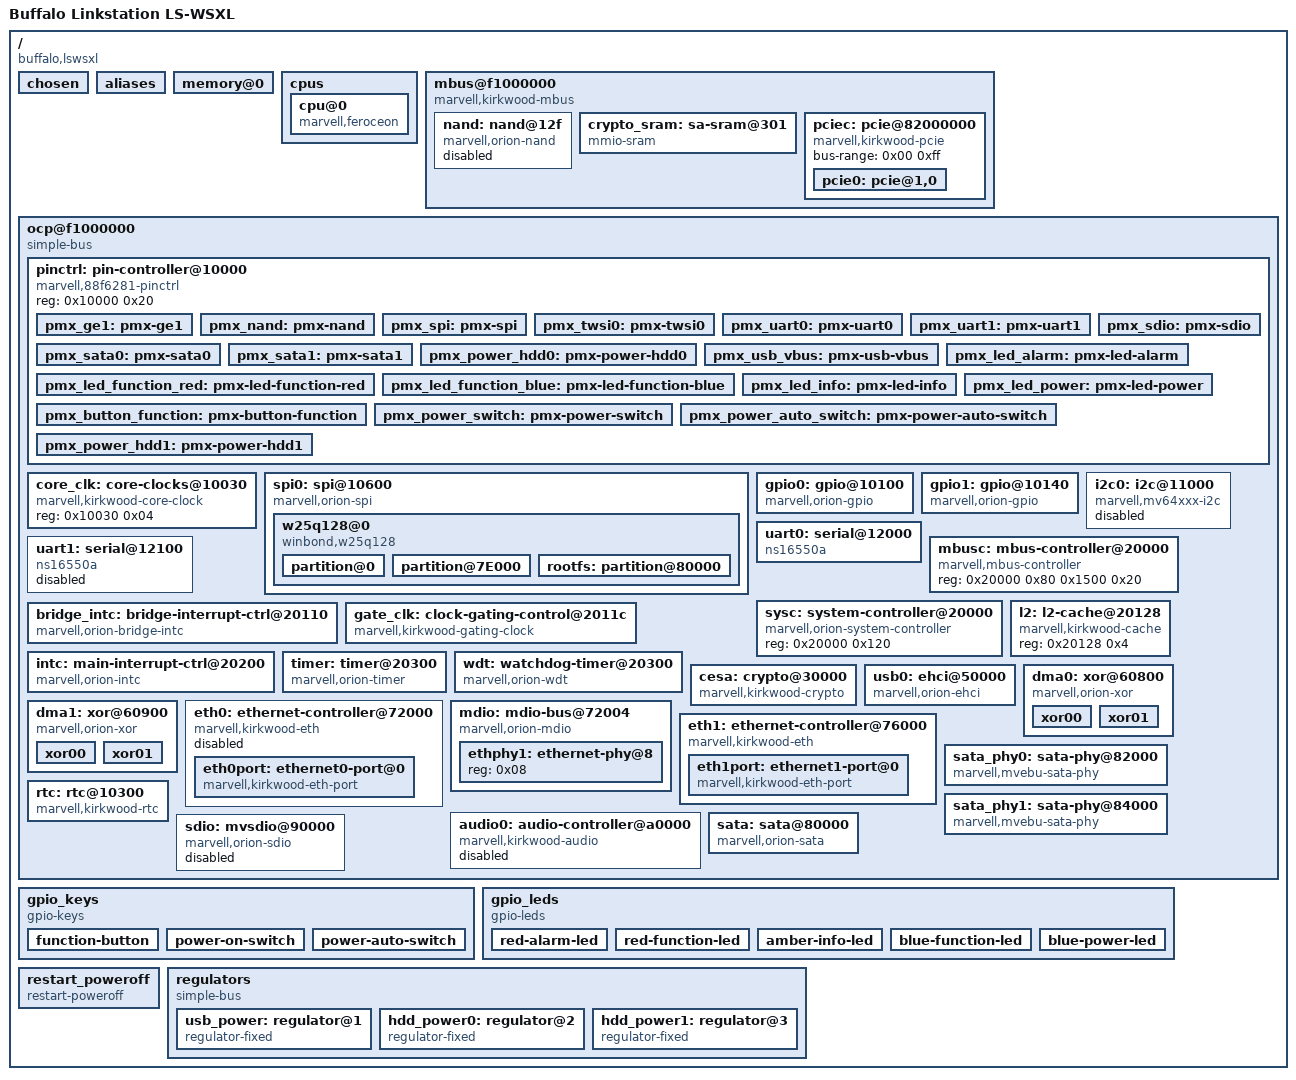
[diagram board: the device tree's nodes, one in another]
/dts-v1/;

#include <dt-bindings/input/input.h>
#include <dt-bindings/gpio/gpio.h>

#define MBUS_ID(target,attributes) (((target) << 24) | ((attributes) << 16))

/ {
	#address-cells = <0x01>;
	#size-cells = <0x01>;
	compatible = "buffalo,lswsxl", "marvell,kirkwood-88f6281", "marvell,kirkwood";
	interrupt-parent = <&intc>;
	model = "Buffalo Linkstation LS-WSXL";

	chosen {
		bootargs = "console=ttyS0,115200n8 earlyprintk ubi.mtd=rootfs root=/dev/ubiblock0_1 rootwait";
		stdout-path = &uart0;
	};

	aliases {
	       gpio0 = &gpio0;
	       gpio1 = &gpio1;
	       i2c0 = &i2c0;
	};

	memory@0 { /* 128 MB */
		name = "memory";
		device_type = "memory";
		reg = <0x00000000 0x8000000>;
	};

	cpus {
		#address-cells = <0x01>;
		#size-cells = <0x00>;

		cpu@0 {
			device_type = "cpu";
			compatible = "marvell,feroceon";
			reg = <0x00>;
			clocks = <&core_clk 1>, <&core_clk 3>, <&gate_clk 11>;
			clock-names = "cpu_clk", "ddrclk", "powersave";
		};
	};

	mbus@f1000000 {
		compatible = "marvell,kirkwood-mbus", "simple-bus";
		#address-cells = <0x02>;
		#size-cells = <0x01>;
		/* If a board file needs to change this ranges it must replace it completely */
		ranges = <MBUS_ID(0xf0, 0x01) 0 0xf1000000 0x100000	/* internal-regs */
			  MBUS_ID(0x01, 0x2f) 0 0xf4000000 0x10000	/* nand flash */
			  MBUS_ID(0x03, 0x01) 0 0xf5000000 0x10000	/* crypto sram */
			  >;
		controller = <&mbusc>;
		pcie-mem-aperture = <0xe0000000 0x10000000>; /* 256 MiB memory space */
		pcie-io-aperture  = <0xf2000000 0x100000>;   /*   1 MiB    I/O space */

		nand: nand@12f {
			#address-cells = <1>;
			#size-cells = <1>;
			cle = <0>;
			ale = <1>;
			bank-width = <1>;
			compatible = "marvell,orion-nand";
			reg = <MBUS_ID(0x01, 0x2f) 0 0x400>;
			chip-delay = <25>;
			/* set partition map and/or chip-delay in board dts */
			clocks = <&gate_clk 7>;
			pinctrl-0 = <&pmx_nand>;
			pinctrl-names = "default";
			status = "disabled";
		};

		crypto_sram: sa-sram@301 {
			compatible = "mmio-sram";
			reg = <MBUS_ID(0x03, 0x01) 0x0 0x800>;
			clocks = <&gate_clk 17>;
			#address-cells = <1>;
			#size-cells = <1>;
		};

		pciec: pcie@82000000 {
			compatible = "marvell,kirkwood-pcie";
			status = "okay";
			device_type = "pci";
			#address-cells = <0x03>;
			#size-cells = <0x02>;
			bus-range = <0x00 0xff>;

			ranges =
			       <0x82000000 0 0x40000 MBUS_ID(0xf0, 0x01) 0x40000 0 0x00002000
				0x82000000 0x1 0     MBUS_ID(0x04, 0xe8) 0       1 0 /* Port 0.0 MEM */
				0x81000000 0x1 0     MBUS_ID(0x04, 0xe0) 0       1 0 /* Port 0.0 IO  */>;

			pcie0: pcie@1,0 {
				device_type = "pci";
				assigned-addresses = <0x82000800 0 0x00040000 0 0x2000>;
				reg = <0x0800 0 0 0 0>;
				#address-cells = <3>;
				#size-cells = <2>;
				#interrupt-cells = <1>;
				ranges = <0x82000000 0 0 0x82000000 0x1 0 1 0
					  0x81000000 0 0 0x81000000 0x1 0 1 0>;
				bus-range = <0x00 0xff>;
				interrupt-map-mask = <0 0 0 0>;
				interrupt-map = <0 0 0 0 &intc 9>;
				marvell,pcie-port = <0>;
				marvell,pcie-lane = <0>;
				clocks = <&gate_clk 2>;
				status = "okay";
			};
		};
	};

	ocp@f1000000 {
		compatible = "simple-bus";
		ranges = <0x00 0xf1000000 0x100000>;
		#address-cells = <0x01>;
		#size-cells = <0x01>;

		pinctrl: pin-controller@10000 {
			reg = <0x10000 0x20>;
			compatible = "marvell,88f6281-pinctrl";

			pmx_ge1: pmx-ge1 {
				marvell,pins = "mpp20", "mpp21", "mpp22", "mpp23",
					       "mpp24", "mpp25", "mpp26", "mpp27",
					       "mpp30", "mpp31", "mpp32", "mpp33";
				marvell,function = "ge1";
			};

			pmx_nand: pmx-nand {
				marvell,pins = "mpp0", "mpp1", "mpp2", "mpp3",
					       "mpp4", "mpp5", "mpp18", "mpp19";
				marvell,function = "nand";
			};

			/*
			 * Default SPI0 pinctrl setting with CSn on mpp0,
			 * overwrite marvell,pins on board level if required.
			 */
			pmx_spi: pmx-spi {
				marvell,pins = "mpp0", "mpp1", "mpp2", "mpp3";
				marvell,function = "spi";
			};

			pmx_twsi0: pmx-twsi0 {
				marvell,pins = "mpp8", "mpp9";
				marvell,function = "twsi0";
			};

			/*
			 * Default UART pinctrl setting without RTS/CTS,
			 * overwrite marvell,pins on board level if required.
			 */
			pmx_uart0: pmx-uart0 {
				marvell,pins = "mpp10", "mpp11";
				marvell,function = "uart0";
			};

			pmx_uart1: pmx-uart1 {
				marvell,pins = "mpp13", "mpp14";
				marvell,function = "uart1";
			};

			pmx_sata0: pmx-sata0 {
				marvell,pins = "mpp5", "mpp21", "mpp23";
				marvell,function = "sata0";
			};

			pmx_sata1: pmx-sata1 {
				marvell,pins = "mpp4", "mpp20", "mpp22";
				marvell,function = "sata1";
			};

			pmx_sdio: pmx-sdio {
				marvell,pins = "mpp12", "mpp13", "mpp14",
					       "mpp15", "mpp16", "mpp17";
			};

			pmx_power_hdd0: pmx-power-hdd0 {
				marvell,function = "gpio";
				marvell,pins = "mpp28";
			};

			pmx_usb_vbus: pmx-usb-vbus {
				marvell,function = "gpio";
				marvell,pins = "mpp37";
			};

			pmx_led_alarm: pmx-led-alarm {
				marvell,function = "gpio";
				marvell,pins = "mpp49";
			};

			pmx_led_function_red: pmx-led-function-red {
				marvell,function = "gpio";
				marvell,pins = "mpp34";
			};

			pmx_led_function_blue: pmx-led-function-blue {
				marvell,function = "gpio";
				marvell,pins = "mpp36";
			};

			pmx_led_info: pmx-led-info {
				marvell,function = "gpio";
				marvell,pins = "mpp38";
			};

			pmx_led_power: pmx-led-power {
				marvell,function = "gpio";
				marvell,pins = "mpp39";
			};

			pmx_button_function: pmx-button-function {
				marvell,function = "gpio";
				marvell,pins = "mpp41";
			};

			pmx_power_switch: pmx-power-switch {
				marvell,function = "gpio";
				marvell,pins = "mpp42";
			};

			pmx_power_auto_switch: pmx-power-auto-switch {
				marvell,function = "gpio";
				marvell,pins = "mpp43";
			};

			pmx_power_hdd1: pmx-power-hdd1 {
				marvell,pins = "mpp35";
				marvell,function = "gpio";
			};
		};

		core_clk: core-clocks@10030 {
			compatible = "marvell,kirkwood-core-clock";
			reg = <0x10030 0x04>;
			#clock-cells = <0x01>;
		};

		spi0: spi@10600 {
			compatible = "marvell,orion-spi";
			#address-cells = <1>;
			#size-cells = <0>;
			cell-index = <0>;
			interrupts = <23>;
			reg = <0x10600 0x28>;
			clocks = <&gate_clk 7>;
			pinctrl-0 = <&pmx_spi>;
			pinctrl-names = "default";
			status = "okay";

			w25q128@0 {
				#address-cells = <0x01>;
				#size-cells = <0x01>;
				compatible = "winbond,w25q128", "jedec,spi-nor";
				reg = <0x00>;
				spi-max-frequency = <50000000>;
				mode = <0x00>;

				partition@0 {
					reg = <0x00 0x70000>;
					label = "uboot";
					read-only;
				};

				partition@7E000 {
					reg = <0x70000 0x10000>;
					label = "uboot_env";
				};

				rootfs:partition@80000 {
					reg = <0x80000 0xF80000>;
					label = "rootfs";
				};
			};
		};

		gpio0: gpio@10100 {
			compatible = "marvell,orion-gpio";
			#gpio-cells = <2>;
			gpio-controller;
			reg = <0x10100 0x40>;
			ngpios = <32>;
			interrupt-controller;
			#interrupt-cells = <2>;
			interrupts = <35>, <36>, <37>, <38>;
			clocks = <&gate_clk 7>;
		};

		gpio1: gpio@10140 {
			compatible = "marvell,orion-gpio";
			#gpio-cells = <2>;
			gpio-controller;
			reg = <0x10140 0x40>;
			ngpios = <18>;
			interrupt-controller;
			#interrupt-cells = <2>;
			interrupts = <39>, <40>, <41>;
			clocks = <&gate_clk 7>;
		};

		i2c0: i2c@11000 {
			compatible = "marvell,mv64xxx-i2c";
			reg = <0x11000 0x20>;
			#address-cells = <1>;
			#size-cells = <0>;
			interrupts = <29>;
			clock-frequency = <100000>;
			clocks = <&gate_clk 7>;
			pinctrl-0 = <&pmx_twsi0>;
			pinctrl-names = "default";
			status = "disabled";
		};

		uart0: serial@12000 {
			compatible = "ns16550a";
			reg = <0x12000 0x100>;
			reg-shift = <2>;
			interrupts = <33>;
			clocks = <&gate_clk 7>;
			pinctrl-0 = <&pmx_uart0>;
			pinctrl-names = "default";
			status = "okay";
		};

		uart1: serial@12100 {
			compatible = "ns16550a";
			reg = <0x12100 0x100>;
			reg-shift = <2>;
			interrupts = <34>;
			clocks = <&gate_clk 7>;
			pinctrl-0 = <&pmx_uart1>;
			pinctrl-names = "default";
			status = "disabled";
		};

		mbusc: mbus-controller@20000 {
			compatible = "marvell,mbus-controller";
			reg = <0x20000 0x80 0x1500 0x20>;
		};

		sysc: system-controller@20000 {
			compatible = "marvell,orion-system-controller";
			reg = <0x20000 0x120>;
		};

		bridge_intc: bridge-interrupt-ctrl@20110 {
			compatible = "marvell,orion-bridge-intc";
			interrupt-controller;
			#interrupt-cells = <1>;
			reg = <0x20110 0x8>;
			interrupts = <1>;
			marvell,#interrupts = <6>;
		};

		gate_clk: clock-gating-control@2011c {
			compatible = "marvell,kirkwood-gating-clock";
			reg = <0x2011c 0x4>;
			clocks = <&core_clk 0>;
			#clock-cells = <1>;
		};

		l2: l2-cache@20128 {
			compatible = "marvell,kirkwood-cache";
			reg = <0x20128 0x4>;
		};

		intc: main-interrupt-ctrl@20200 {
			compatible = "marvell,orion-intc";
			interrupt-controller;
			#interrupt-cells = <1>;
			reg = <0x20200 0x10>, <0x20210 0x10>;
		};

		timer: timer@20300 {
			compatible = "marvell,orion-timer";
			reg = <0x20300 0x20>;
			interrupt-parent = <&bridge_intc>;
			interrupts = <1>, <2>;
			clocks = <&core_clk 0>;
		};

		wdt: watchdog-timer@20300 {
			compatible = "marvell,orion-wdt";
			reg = <0x20300 0x28>, <0x20108 0x4>;
			interrupt-parent = <&bridge_intc>;
			interrupts = <3>;
			clocks = <&gate_clk 7>;
			status = "okay";
		};

		cesa: crypto@30000 {
			compatible = "marvell,kirkwood-crypto";
			reg = <0x30000 0x10000>;
			reg-names = "regs";
			interrupts = <22>;
			clocks = <&gate_clk 17>;
			marvell,crypto-srams = <&crypto_sram>;
			marvell,crypto-sram-size = <0x800>;
			status = "okay";
		};

		usb0: ehci@50000 {
			compatible = "marvell,orion-ehci";
			reg = <0x50000 0x1000>;
			interrupts = <19>;
			clocks = <&gate_clk 3>;
			status = "okay";
		};

		dma0: xor@60800 {
			compatible = "marvell,orion-xor";
			reg = <0x60800 0x100
			       0x60A00 0x100>;
			status = "okay";
			clocks = <&gate_clk 8>;

			xor00 {
			      interrupts = <5>;
			      dmacap,memcpy;
			      dmacap,xor;
			};

			xor01 {
			      interrupts = <6>;
			      dmacap,memcpy;
			      dmacap,xor;
			      dmacap,memset;
			};
		};

		dma1: xor@60900 {
			compatible = "marvell,orion-xor";
			reg = <0x60900 0x100
			       0x60B00 0x100>;
			status = "okay";
			clocks = <&gate_clk 16>;

			xor00 {
			      interrupts = <7>;
			      dmacap,memcpy;
			      dmacap,xor;
			};

			xor01 {
			      interrupts = <8>;
			      dmacap,memcpy;
			      dmacap,xor;
			      dmacap,memset;
			};
		};

		eth0: ethernet-controller@72000 {
			compatible = "marvell,kirkwood-eth";
			#address-cells = <1>;
			#size-cells = <0>;
			reg = <0x72000 0x4000>;
			clocks = <&gate_clk 0>;
			marvell,tx-checksum-limit = <1600>;
			status = "disabled";

			eth0port: ethernet0-port@0 {
				compatible = "marvell,kirkwood-eth-port";
				reg = <0>;
				interrupts = <11>;
				/* overwrite MAC address in bootloader */
				local-mac-address = [00 00 00 00 00 00];
				/* set phy-handle property in board file */
			};
		};

		mdio: mdio-bus@72004 {
			compatible = "marvell,orion-mdio";
			#address-cells = <1>;
			#size-cells = <0>;
			reg = <0x72004 0x84>;
			interrupts = <46>;
			clocks = <&gate_clk 0>;
			status = "okay";

			ethphy1: ethernet-phy@8 {
				device_type = "ethernet-phy";
				reg = <0x08>;
			};
		};

		eth1: ethernet-controller@76000 {
			compatible = "marvell,kirkwood-eth";
			#address-cells = <1>;
			#size-cells = <0>;
			reg = <0x76000 0x4000>;
			clocks = <&gate_clk 19>;
			marvell,tx-checksum-limit = <1600>;
			pinctrl-0 = <&pmx_ge1>;
			pinctrl-names = "default";
			status = "okay";

			eth1port: ethernet1-port@0 {
				compatible = "marvell,kirkwood-eth-port";
				reg = <0>;
				interrupts = <15>;
				/* overwrite MAC address in bootloader */
				local-mac-address = [00 00 00 00 00 00];
				/* set phy-handle property in board file */
				phy-handle = <&ethphy1>;
			};
		};

		sata_phy0: sata-phy@82000 {
			compatible = "marvell,mvebu-sata-phy";
			reg = <0x82000 0x0334>;
			clocks = <&gate_clk 14>;
			clock-names = "sata";
			#phy-cells = <0>;
			status = "ok";
		};

		sata_phy1: sata-phy@84000 {
			compatible = "marvell,mvebu-sata-phy";
			reg = <0x84000 0x0334>;
			clocks = <&gate_clk 15>;
			clock-names = "sata";
			#phy-cells = <0>;
			status = "ok";
		};

		audio0: audio-controller@a0000 {
			compatible = "marvell,kirkwood-audio";
			#sound-dai-cells = <0>;
			reg = <0xa0000 0x2210>;
			interrupts = <24>;
			clocks = <&gate_clk 9>;
			clock-names = "internal";
			status = "disabled";
		};


		rtc: rtc@10300 {
			compatible = "marvell,kirkwood-rtc", "marvell,orion-rtc";
			reg = <0x10300 0x20>;
			interrupts = <53>;
			clocks = <&gate_clk 7>;
		};


		sata: sata@80000 {
			compatible = "marvell,orion-sata";
			reg = <0x80000 0x5000>;
			interrupts = <21>;
			clocks = <&gate_clk 14>, <&gate_clk 15>;
			clock-names = "0", "1";
			phys = <&sata_phy0>, <&sata_phy1>;
			phy-names = "port0", "port1";
			status = "okay";
			nr-ports = <0x02>;
		};

		sdio: mvsdio@90000 {
			compatible = "marvell,orion-sdio";
			reg = <0x90000 0x200>;
			interrupts = <28>;
			clocks = <&gate_clk 4>;
			pinctrl-0 = <&pmx_sdio>;
			pinctrl-names = "default";
			bus-width = <4>;
			cap-sdio-irq;
			cap-sd-highspeed;
			cap-mmc-highspeed;
			status = "disabled";
		};
	};

	gpio_keys {
		compatible = "gpio-keys";
		#address-cells = <0x01>;
		#size-cells = <0x00>;
		pinctrl-0 = <&pmx_button_function &pmx_power_switch
			     &pmx_power_auto_switch>;
		pinctrl-names = "default";

		function-button {
			label = "Function Button";
			linux,code = <KEY_OPTION>;
			gpios = <&gpio1 9 GPIO_ACTIVE_LOW>;
		};

		power-on-switch {
			label = "Power-on Switch";
			linux,code = <KEY_RESERVED>;
			linux,input-type = <0x05>;
			gpios = <&gpio1 10 GPIO_ACTIVE_LOW>;
		};

		power-auto-switch {
			label = "Power-auto Switch";
			linux,code = <KEY_ESC>;
			linux,input-type = <0x05>;
			gpios = <&gpio1 11 GPIO_ACTIVE_LOW>;
		};
	};

	gpio_leds {
		compatible = "gpio-leds";
		pinctrl-0 = <&pmx_led_function_red &pmx_led_alarm
			     &pmx_led_info &pmx_led_power
			     &pmx_led_function_blue>;
		pinctrl-names = "default";

		red-alarm-led {
			label = "linkstation:red:alarm";
			gpios = <&gpio1 17 GPIO_ACTIVE_LOW>;
		};

		red-function-led {
			label = "linkstation:red:function";
			gpios = <&gpio1 2 GPIO_ACTIVE_HIGH>;
		};

		amber-info-led {
			label = "linkstation:amber:info";
			gpios = <&gpio1 6 GPIO_ACTIVE_LOW>;
		};

		blue-function-led {
			label = "linkstation:blue:function";
			gpios = <&gpio1 4 GPIO_ACTIVE_LOW>;
		};

		blue-power-led {
			label = "linkstation:blue:power";
			gpios = <&gpio1 7 GPIO_ACTIVE_HIGH>;
			default-state = "keep";
		};
	};

	restart_poweroff {
		compatible = "restart-poweroff";
	};

	regulators {
		compatible = "simple-bus";
		#address-cells = <0x01>;
		#size-cells = <0x00>;
		pinctrl-0 = <&pmx_power_hdd0 &pmx_power_hdd1 &pmx_usb_vbus>;
		pinctrl-names = "default";

		usb_power: regulator@1 {
			compatible = "regulator-fixed";
			reg = <1>;
			regulator-name = "USB Power";
			regulator-min-microvolt = <5000000>;
			regulator-max-microvolt = <5000000>;
			enable-active-high;
			regulator-always-on;
			regulator-boot-on;
			gpio = <&gpio1 5 GPIO_ACTIVE_HIGH>;
		};

		hdd_power0: regulator@2 {
			compatible = "regulator-fixed";
			reg = <2>;
			regulator-name = "HDD0 Power";
			regulator-min-microvolt = <5000000>;
			regulator-max-microvolt = <5000000>;
			enable-active-high;
			regulator-always-on;
			regulator-boot-on;
			gpio = <&gpio0 28 GPIO_ACTIVE_HIGH>;
		};

		hdd_power1: regulator@3 {
			compatible = "regulator-fixed";
			reg = <3>;
			regulator-name = "HDD1 Power";
			regulator-min-microvolt = <5000000>;
			regulator-max-microvolt = <5000000>;
			enable-active-high;
			regulator-always-on;
			regulator-boot-on;
			gpio = <&gpio1 3 GPIO_ACTIVE_HIGH>;
		};
	};
};
